# TC37X register map
File version: 1.0.0
CPU: CM4 r0p1, little endian, MPU, FPU, VTOR, 3 interrupt priority bits
Registers are 16-bit, read-write, reset 0x0 unless marked. A register's access mark holds for its fields unless they carry their own. Offsets are from the block's base; [hi:lo] are bit positions; {n}, {i} and the like mark numbered series; 'fields as' and 'values as' point back to an identical list.

## FSI — ce_fsi
Base 0xF8030000
0x04 COMM_1 8-bit — Communication Register 1
  [7:0] COMM1 — FSI Communication 1 - COMM1
0x05 COMM_2 8-bit — Communication Register 2
  [7:0] COMM2 — FSI Communication 2 - COMM2
0x06 HSMCOMM_1 8-bit — HSM Communication Register 1
  [7:0] HSMCOMM1 — HSM FSI Communication 1 - HSMCOMM1
0x07 HSMCOMM_2 8-bit — HSM Communication Register 2
  [7:0] HSMCOMM2 — HSM FSI Communication 2 - HSMCOMM2

## PMU — ce_pmu
Base 0xF8038000
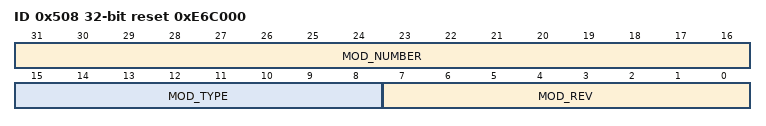
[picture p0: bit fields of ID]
0x508 ID 32-bit ro reset 0xE6C000 (reset mask 0xFFFFFF00) — Module Identification Register
  [31:16] MOD_NUMBER — Module Number Value - MOD_NUMBER
  [15:8] MOD_TYPE — Module Type - MOD_TYPE
  [7:0] MOD_REV — Module Revision Number - MOD_REV

## ADMA0 — ce_adma
Base 0xF8508400
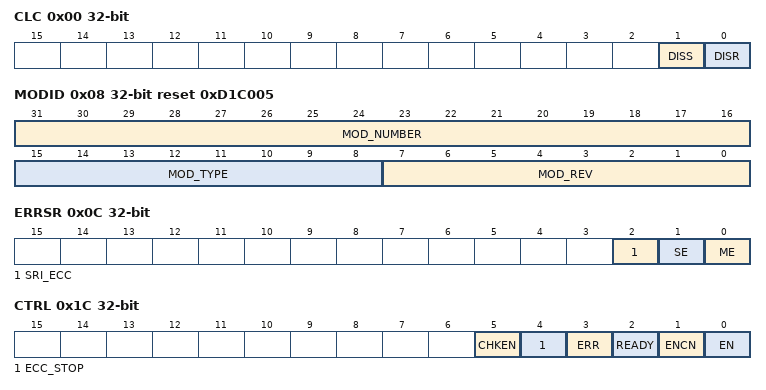
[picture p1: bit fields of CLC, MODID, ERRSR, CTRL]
0x00 CLC 32-bit — Clock Control Register
  [1] DISS ro — Module Disable Status Bit - DISS
  [0] DISR — Module Disable Request Bit - DISR
0x08 MODID 32-bit ro reset 0xD1C005 — Module Identification Register
  [31:16] MOD_NUMBER — Module Number Value - MOD_NUMBER
  [15:8] MOD_TYPE — Module Type - MOD_TYPE
  [7:0] MOD_REV — Module Revision Number - MOD_REV
0x0C ERRSR 32-bit ro — Error Status Register
  [2] SRI_ECC — System Memory ECC Error - SRI_ECC
  [1] SE — System Error - SE
  [0] ME — Memory Error - ME
0x10 SADR 32-bit — Source Address Register
  [31:0] SADR — Source Address Register (Pointer) - SADR
0x14 DADR 32-bit — Destination Address Register
  [31:0] DADR — Destination Address Register (Pointer) - DADR
0x18 CNT 32-bit — Counter Register
  [31:0] CNT — Byte Counter - CNT
0x1C CTRL 32-bit — Control Register
  [5] CHKEN — Checksum Enable Mode Bit - CHKEN
  [4] ECC_STOP — ECC Error Mode Bit - ECC_STOP
  [3] ERR ro — Error Interrupt - ERR
  [2] READY ro — Ready Flag - READY
  [1] ENCN — Enable Condition Bit - ENCN
  [0] EN — Enable Bit - EN
0x20 CHKSUM 32-bit — Checksum Register
  [31:0] CHKSUM — DATA Checksum - CHKSUM
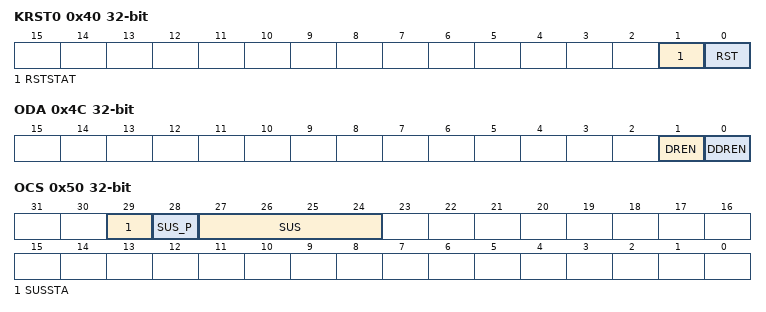
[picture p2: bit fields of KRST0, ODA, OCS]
0x40 KRST0 32-bit — Kernel Reset Register 0
  [1] RSTSTAT ro — Kernel Reset Status - RSTSTAT
  [0] RST — Kernel Reset - RST
0x44 KRST1 32-bit — Kernel Reset Register 1
  [0] RST — Kernel Reset - RST
0x48 KRSTCLR 32-bit wo — Kernel Reset Status Clear Register
  [0] CLR — Kernel Reset Status Clear - CLR
0x4C ODA 32-bit — OCDS Debug Access Register
  [1] DREN — Destructive Read Enable - DREN
  [0] DDREN — Destructive Debug Read Enable - DDREN
0x50 OCS 32-bit — OCDS Control and Status Register
  [29] SUSSTA ro — Suspend State - SUSSTA
  [28] SUS_P wo — SUS Write Protection - SUS_P
  [27:24] SUS — OCDS Suspend Control - SUS

## DAM0 — ce_dam
Base 0xF8500000
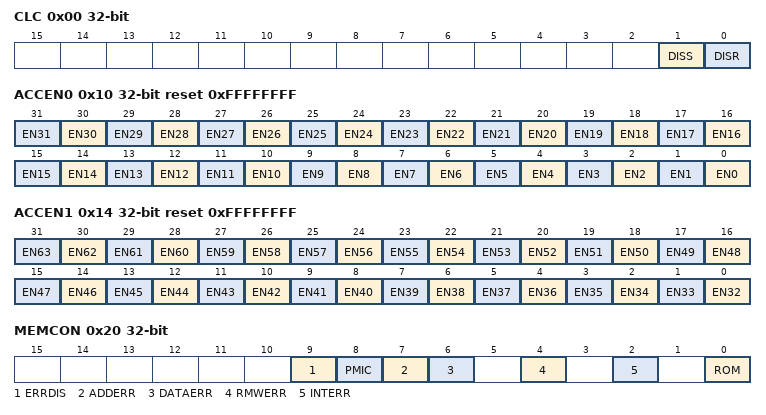
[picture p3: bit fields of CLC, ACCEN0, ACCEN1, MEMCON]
0x00 CLC 32-bit — DAM Clock Control Register
  [1] DISS ro — DAM Disable Status Bit - DISS
  [0] DISR — DAM Disable Request Bit - DISR
0x08 MODID 32-bit ro reset 0x88C003 — DAM Module ID Register
  [31:0] ID_VALUE — Module Identification Value - ID_VALUE
0x10 ACCEN0 32-bit reset 0xFFFFFFFF — DAM Access Enable Register 0
  [n] EN{n} (n=0..31) — Access Enable for Master TAG ID {n} - EN{n}
0x14 ACCEN1 32-bit reset 0xFFFFFFFF — DAM Access Enable Register 1
  [n-32] EN{n} (n=32..63) — Access Enable for Master TAG ID {n} - EN{n}
0x20 MEMCON 32-bit — DAM Memory Control Register
  [9] ERRDIS — ECC Error Disable - ERRDIS
  [8] PMIC wo — Protection Bit for Memory Integrity Control Bit - PMIC
  [7] ADDERR — SRI Address Phase ECC Error - ADDERR
  [6] DATAERR — SRI Data Phase ECC Error - DATAERR
  [4] RMWERR — Internal Read Modify Write Error - RMWERR
  [2] INTERR — Internal ECC Error - INTERR
  [0] ROM — Read Only Memory - ROM
{0x50+0x10*i} RGNLA{i} 32-bit (i=0..7) — DAM Region Lower Address Register
  [31:5] ADDR — Region Lower Address - ADDR
{0x54+0x10*i} RGNUA{i} 32-bit reset 0xFFFFFFE0 (i=0..7) — DAM Region Upper Address Register
  [31:5] ADDR — Region Lower Address - ADDR
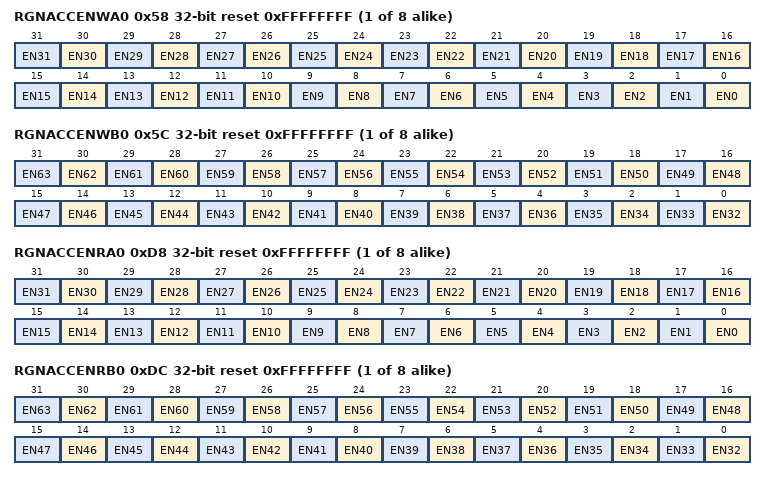
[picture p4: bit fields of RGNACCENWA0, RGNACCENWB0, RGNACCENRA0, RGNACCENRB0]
{0x58+0x10*i} RGNACCENWA{i} 32-bit reset 0xFFFFFFFF (i=0..7) — DAM Region Write Enable Register A
  [n] EN{n} (n=0..31) — Access Enable for Master TAG ID {n} - EN{n}
{0x5C+0x10*i} RGNACCENWB{i} 32-bit reset 0xFFFFFFFF (i=0..7) — DAM Region Write Enable Register B
  fields as ACCEN1
{0xD8+0x10*i} RGNACCENRA{i} 32-bit reset 0xFFFFFFFF (i=0..7) — DAM Region Read Enable Register A
  [n] EN{n} (n=0..31) — Access Enable for Master TAG ID {n} - EN{n}
{0xDC+0x10*i} RGNACCENRB{i} 32-bit reset 0xFFFFFFFF (i=0..7) — DAM Region Read Enable Register B
  fields as ACCEN1
